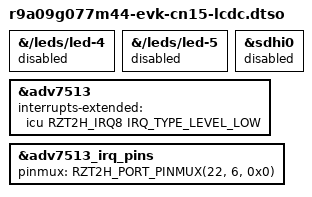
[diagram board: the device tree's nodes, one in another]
// SPDX-License-Identifier: GPL-2.0
/*
 * DT overlay for the RZ/T2H EVK with ADV7513 transmitter
 * connected to DU enabled.
 *
 * Copyright (C) 2026 Renesas Electronics Corp.
 */

/dts-v1/;
/plugin/;

#include <dt-bindings/interrupt-controller/irq.h>

#define RZT2H_IRQ8	24

/*
 * RZ/T2H LCDC configuration:
 * ----------------------------------------------------------
 * Function        Pin     SW Setting
 * ----------------------------------------------------------
 * LCDC_DATG0     P11_0, SW6[3]: OFF, SW6[4]: ON, SW6[5]: OFF
 * LCDC_DATB1     P18_0, SW8[3]: OFF, SW8[4]: ON
 * LCDC_DATB2     P18_1, SW8[1]: OFF, SW8[2]: ON
 * IRQ8           P22_6, SW2[1]: ON, SW2[2]: OFF
 */

&{/leds/led-4} {
	/* P18_0 is used for DU function LCDC_DATB1. */
	status = "disabled";
};

&{/leds/led-5} {
	/* P18_1 is used for DU function LCDC_DATB2. */
	status = "disabled";
};

/*
 * Disable SDHI0 as SW2 settings for eMMC/SD card conflict with DU pin
 * settings.
 */
&sdhi0 {
	status = "disabled";
};

#include "rzt2h-n2h-evk-du-adv7513.dtsi"

&adv7513 {
	interrupts-extended = <&icu RZT2H_IRQ8 IRQ_TYPE_LEVEL_LOW>;
};

&adv7513_irq_pins {
	pinmux = <RZT2H_PORT_PINMUX(22, 6, 0x0)>; /* IRQ8 */
};
